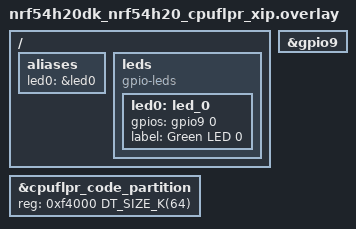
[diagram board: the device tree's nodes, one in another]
/*
 * Copyright (c) 2026 Nordic Semiconductor ASA
 *
 * SPDX-License-Identifier: Apache-2.0
 *
 */

/ {
	aliases {
		led0 = &led0;
	};

	leds {
		compatible = "gpio-leds";

		led0: led_0 {
			gpios = <&gpio9 0 GPIO_ACTIVE_HIGH>;
			label = "Green LED 0";
		};
	};
};

&gpio9 {
	status = "okay";
};

&cpuflpr_code_partition {
	reg = <0xf4000 DT_SIZE_K(64)>;
};
